# STM32H725xx register map
File version: 1.0
Registers are 32-bit, read-write, reset 0x0 unless marked. A register's access mark holds for its fields unless they carry their own. Offsets are from the block's base; [hi:lo] are bit positions; {n}, {i} and the like mark numbered series; 'fields as' and 'values as' point back to an identical list.

## RNG
Base 0x48021800
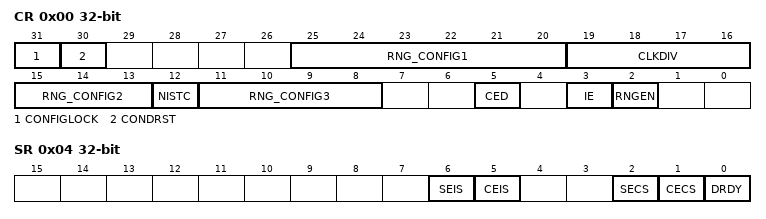
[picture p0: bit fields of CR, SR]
0x00 CR — RNG control register
  [31] CONFIGLOCK
  [30] CONDRST
  [25:20] RNG_CONFIG1
  [19:16] CLKDIV
    0=BY_1 (No clock division); 1=BY_2 (2 RNG clock cycles per internal RNG clock); 2=BY_4 (4 RNG clock cycles per internal RNG clock); 3=BY_8 (8 RNG clock cycles per internal RNG clock); 4=BY_16 (16 RNG clock cycles per internal RNG clock); 5=BY_32 (32 RNG clock cycles per internal RNG clock); 6=BY_64 (64 RNG clock cycles per internal RNG clock); 7=BY_128 (128 RNG clock cycles per internal RNG clock); 8=BY_256 (256 RNG clock cycles per internal RNG clock); 9=BY_512 (512 RNG clock cycles per internal RNG clock); 10=BY_1024 (1024 RNG clock cycles per internal RNG clock); 11=BY_2048 (2048 RNG clock cycles per internal RNG clock); 12=BY_4096 (4096 RNG clock cycles per internal RNG clock); 13=BY_8192 (8192 RNG clock cycles per internal RNG clock); 14=BY_16384 (16384 RNG clock cycles per internal RNG clock); 15=BY_32768 (32768 RNG clock cycles per internal RNG clock)
  [15:13] RNG_CONFIG2
  [12] NISTC
  [11:8] RNG_CONFIG3
  [5] CED
  [3] IE
  [2] RNGEN
0x04 SR — RNG status register
  [6] SEIS, [5] CEIS, [2] SECS, [1] CECS, [0] DRDY
0x08 DR — RNG data register
0x10 HTCR — RNG health test configuration register

## DLYB_SDMMC2 — Delay Block DLYB
Base 0x48022800
Same registers: DLYB_OCTOSPI1 0x52006000, DLYB_SDMMC1 0x52008000, DLYB_OCTOSPI2 0x5200B000
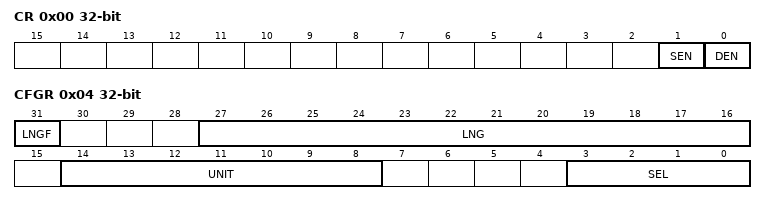
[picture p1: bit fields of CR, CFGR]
0x00 CR — DELAY BLOCK control register
  [1] SEN — Sampler length enable
  [0] DEN — Delay Block enable
0x04 CFGR — DELAY BLOCK configuration register
  [31] LNGF — Length valid flag
  [27:16] LNG — Delay line length value[11:0]
  [14:8] UNIT — Delay Defines the delay of a Unit delay cell[6:0]
  [3:0] SEL — Select the phase for the Output clock[3:0]

## RAMECC2
Base 0x48023000
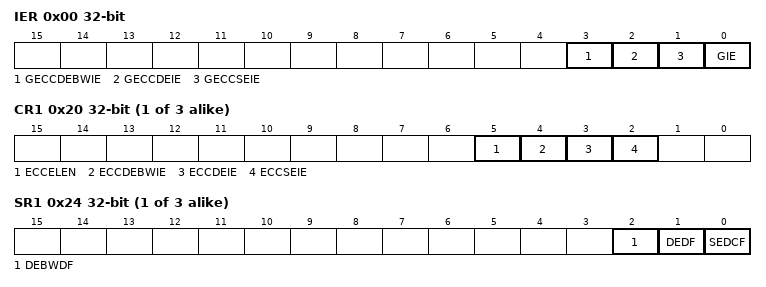
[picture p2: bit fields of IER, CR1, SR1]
0x00 IER — RAMECC interrupt enable register
  [3] GECCDEBWIE — Global ECC double error on byte write (BW) interrupt enable
  [2] GECCDEIE — Global ECC double error interrupt enable
  [1] GECCSEIE — Global ECC single error interrupt enable
  [0] GIE — Global interrupt enable
{0x0+0x20*i} CR{i} (i=1..3) — RAMECC monitor configuration register
  [5] ECCELEN — ECC error latching enable
  [4] ECCDEBWIE — ECC double error on byte write (BW) interrupt enable
  [3] ECCDEIE — ECC double error interrupt enable
  [2] ECCSEIE — ECC single error interrupt enable
{0x4+0x20*i} SR{i} (i=1..3) — RAMECC monitor status register
  [2] DEBWDF — ECC double error on byte write (BW) detected flag
  [1] DEDF — ECC double error detected flag
  [0] SEDCF — ECC single error detected and corrected flag
{0x8+0x20*i} FAR{i} (i=1..3) — RAMECC monitor failing address register
  [31:0] FADD — ECC error failing address
{0xC+0x20*i} FDRL{i} (i=1..3) — RAMECC monitor failing data low register
{0x10+0x20*i} FDRH{i} (i=1..3) — RAMECC monitor failing data high register
{0x14+0x20*i} FECR{i} (i=1..3) — RAMECC monitor failing ECC error code register
  [31:0] FEC — Failing error code

## RAMECC1
Base 0x52009000
Registers as RAMECC2; these are added or differ:
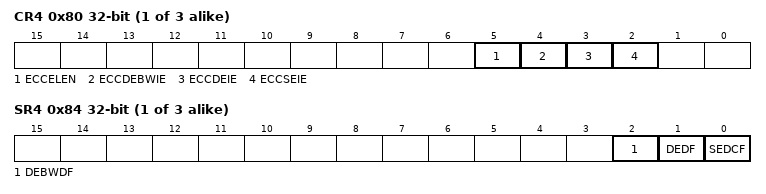
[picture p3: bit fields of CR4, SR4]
{0x0+0x20*i} CR{i} (i=4..6) — RAMECC monitor configuration register
  fields as RAMECC2.CR1
{0x4+0x20*i} SR{i} (i=4..6) — RAMECC monitor status register
  [2] DEBWDF — ECC double error on byte write (BW) detected flag
  [1] DEDF — ECC double error detected flag
  [0] SEDCF — ECC single error detected and corrected flag
{0x8+0x20*i} FAR{i} (i=4..6) — RAMECC monitor failing address register
  [31:0] FADD — ECC error failing address
{0xC+0x20*i} FDRL{i} (i=4..6) — RAMECC monitor failing data low register
{0x10+0x20*i} FDRH{i} (i=4..6) — RAMECC monitor failing data high register
{0x14+0x20*i} FECR{i} (i=4..6) — RAMECC monitor failing ECC error code register
  [31:0] FEC — Failing error code

## RAMECC3
Base 0x58027000
Registers as RAMECC2, without CR3, SR3, FAR3, FDRL3, FDRH3, FECR3.
